# MDR32F8 register map
Vendor: Milandr; File version: 1.0
CPU: CM4 r1p1, little endian, no MPU, FPU, 3 interrupt priority bits
Registers are 32-bit, read-write, reset 0x0 unless marked. A register's access mark holds for its fields unless they carry their own. Offsets are from the block's base; [hi:lo] are bit positions; {n}, {i} and the like mark numbered series.

## MDR_EEPROM — Flash programm memory interfase controller registers
Base 0x40018000; register names take the prefix MDR_EEPROM_
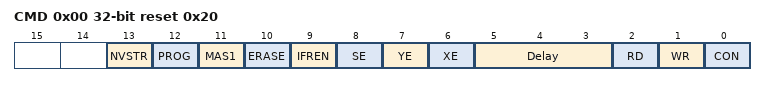
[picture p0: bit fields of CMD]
0x00 CMD reset 0x20 — EEPROM Command Register
  [13] NVSTR, [12] PROG, [11] MAS1, [10] ERASE, [9] IFREN, [8] SE, [7] YE, [6] XE, [5:3] Delay, [2] RD, [1] WR, [0] CON
0x04 ADR — EEPROM Address Register
0x08 DI — EEPROM Read Data Register
  [31:0] DATA
0x0C DO — EEPROM Write Data Register
  [31:0] DATA
0x10 KEY — EEPROM Key Register

## MDR_RST_CLK — RST_CLK
Base 0x40020000; register names take the prefix MDR_RST_CLK_
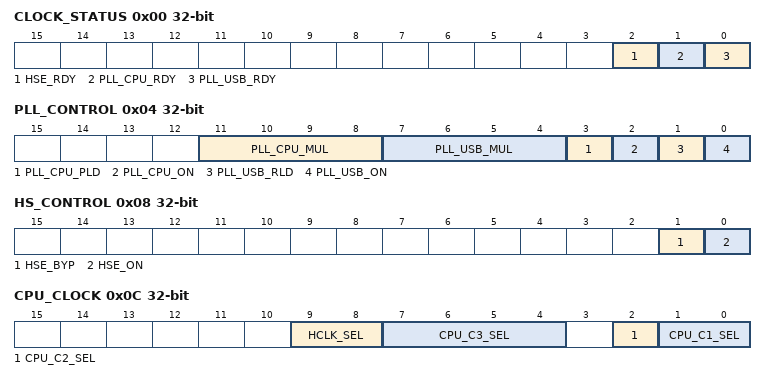
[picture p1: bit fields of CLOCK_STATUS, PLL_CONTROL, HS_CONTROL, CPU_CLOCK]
0x00 CLOCK_STATUS ro
  [2] HSE_RDY, [1] PLL_CPU_RDY, [0] PLL_USB_RDY
0x04 PLL_CONTROL
  [11:8] PLL_CPU_MUL, [7:4] PLL_USB_MUL, [3] PLL_CPU_PLD, [2] PLL_CPU_ON, [1] PLL_USB_RLD, [0] PLL_USB_ON
0x08 HS_CONTROL
  [1] HSE_BYP, [0] HSE_ON
0x0C CPU_CLOCK
  [9:8] HCLK_SEL, [7:4] CPU_C3_SEL, [2] CPU_C2_SEL, [1:0] CPU_C1_SEL
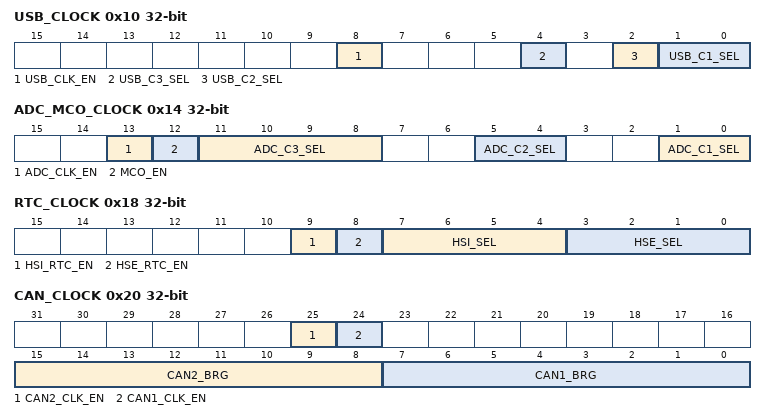
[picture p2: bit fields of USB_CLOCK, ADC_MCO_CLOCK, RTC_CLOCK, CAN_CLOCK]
0x10 USB_CLOCK
  [8] USB_CLK_EN, [4] USB_C3_SEL, [2] USB_C2_SEL, [1:0] USB_C1_SEL
0x14 ADC_MCO_CLOCK — ADC Clock Register
  [13] ADC_CLK_EN, [12] MCO_EN, [11:8] ADC_C3_SEL, [5:4] ADC_C2_SEL, [1:0] ADC_C1_SEL
0x18 RTC_CLOCK
  [9] HSI_RTC_EN, [8] HSE_RTC_EN, [7:4] HSI_SEL, [3:0] HSE_SEL
0x1C PER_CLOCK — Peripheral Clock Enable Register
  [31:0] PCLK_EN
0x20 CAN_CLOCK
  [25] CAN2_CLK_EN, [24] CAN1_CLK_EN, [15:8] CAN2_BRG, [7:0] CAN1_BRG
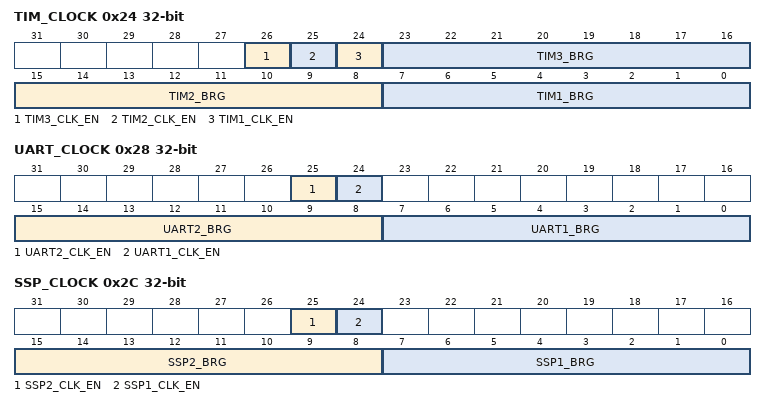
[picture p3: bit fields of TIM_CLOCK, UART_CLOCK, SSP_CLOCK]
0x24 TIM_CLOCK — Timer Clock Register
  [26] TIM3_CLK_EN, [25] TIM2_CLK_EN, [24] TIM1_CLK_EN, [23:16] TIM3_BRG, [15:8] TIM2_BRG, [7:0] TIM1_BRG
0x28 UART_CLOCK
  [25] UART2_CLK_EN, [24] UART1_CLK_EN, [15:8] UART2_BRG, [7:0] UART1_BRG
0x2C SSP_CLOCK
  [25] SSP2_CLK_EN, [24] SSP1_CLK_EN, [15:8] SSP2_BRG, [7:0] SSP1_BRG

## MDR_WDT — Watch Dog Timer
Base 0x40004000
0x00 KEY — Key lock Register
0x04 PRL
0x08 EN — EN Register: Counter run - 0x03333
0x0C CNT

## MDR_EBC — External Bus Control
Base 0x40005000
0x00 KEY — Key lock Register
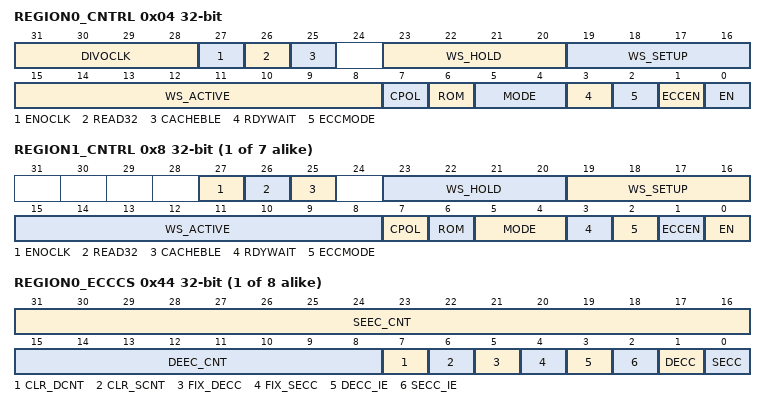
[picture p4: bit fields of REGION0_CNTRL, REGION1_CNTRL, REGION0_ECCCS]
0x04 REGION0_CNTRL
  [31:28] DIVOCLK
  [27] ENOCLK — 0 - OCL OFF, 1 - OCL ON
  [26] READ32
  [25] CACHEBLE — 0 - CACHEBLE OFF, 1 - CACHEBLE ON
  [23:20] WS_HOLD — T = HCLK*(WS_HOLD+1)
  [19:16] WS_SETUP — T = HCLK*(WS_SETUP+1)
  [15:8] WS_ACTIVE — T = HCLK*(WS_ACTIVE+1)
  [7] CPOL — Clock in Active: 0 - Rise, 1 - Fall
  [6] ROM — 0 - RAM, 1 - ROM
  [5:4] MODE — MODE[1:0]: 00 - 32, 01 - 16, 10 - 8, 11 - 64
  [3] RDYWAIT
  [2] ECCMODE — 0 - parallel ECC, 1 - serial ECC
  [1] ECCEN — 0 - ECC OFF, 1 - ECC ON
  [0] EN — 0 - Region OFF, 1 - Region ON
{0x4+4i} REGION{i}_CNTRL (i=1..7)
  [27] ENOCLK — 0 - OCL OFF, 1 - OCL ON
  [26] READ32
  [25] CACHEBLE — 0 - CACHEBLE OFF, 1 - CACHEBLE ON
  [23:20] WS_HOLD — T = HCLK*(WS_HOLD+1)
  [19:16] WS_SETUP — T = HCLK*(WS_SETUP+1)
  [15:8] WS_ACTIVE — T = HCLK*(WS_ACTIVE+1)
  [7] CPOL — Clock in Active: 0 - Rise, 1 - Fall
  [6] ROM — 0 - RAM, 1 - ROM
  [5:4] MODE — MODE[1:0]: 00 - 32, 01 - 16, 10 - 8, 11 - 64
  [3] RDYWAIT
  [2] ECCMODE — 0 - parallel ECC, 1 - serial ECC
  [1] ECCEN — 0 - ECC OFF, 1 - ECC ON
  [0] EN — 0 - Region OFF, 1 - Region ON
{0x24+4i} REGION{i}_ECCBASE (i=0..7)
{0x44+4i} REGION{i}_ECCCS (i=0..7)
  [31:16] SEEC_CNT, [15:8] DEEC_CNT, [7] CLR_DCNT, [6] CLR_SCNT, [5] FIX_DECC, [4] FIX_SECC, [3] DECC_IE, [2] SECC_IE, [1] DECC, [0] SECC
0x94 ECCADR
0x98 ECCDATA
0x9C ECCECC (reset mask 0xFF)

## MDR_OTP — OTP Memory Control
Base 0x40006000
0x00 KEY — Key lock Register
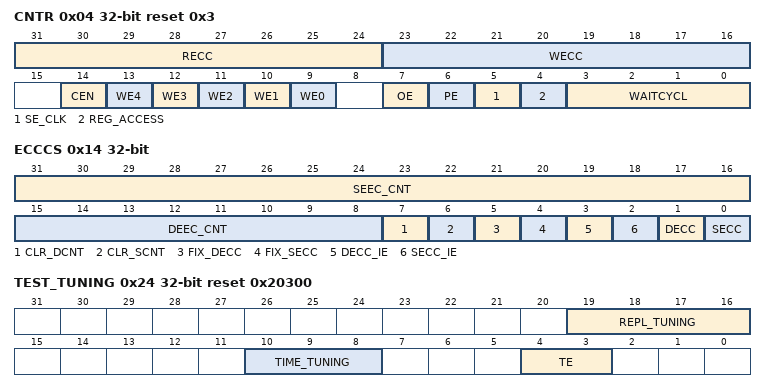
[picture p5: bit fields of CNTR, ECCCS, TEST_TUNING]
0x04 CNTR reset 0x3
  [31:24] RECC
  [23:16] WECC
  [14] CEN — CEN only for RAM (1986VE81T)
  [n+9] WE{n} (n=0..4) — WE only for RAM (1986VE81T)
  [7] OE — OE only for RAM (1986VE81T)
  [6] PE — PE only for OTP (1986VE8T)
  [5] SE_CLK — SE for OTP (1986VE8T), CLK for RAM (1986VE81T)
  [4] REG_ACCESS
  [3:0] WAITCYCL
0x08 ADR
0x0C WDATA
  [31:0] DATA
0x10 RDATA
  [31:0] DATA
0x14 ECCCS
  [31:16] SEEC_CNT, [15:8] DEEC_CNT, [7] CLR_DCNT, [6] CLR_SCNT, [5] FIX_DECC, [4] FIX_SECC, [3] DECC_IE, [2] SECC_IE, [1] DECC, [0] SECC
0x18 ECCADR
0x1C ECCDATA
0x20 ECCECC
  [7:0] ECC
0x24 TEST_TUNING reset 0x20300
  [19:16] REPL_TUNING, [10:8] TIME_TUNING, [4:3] TE

## MDR_RAMD — RAMD Control
Base 0x40008000
Same registers: MDR_ROM 0x40009000
0x00 KEY — Key lock Register
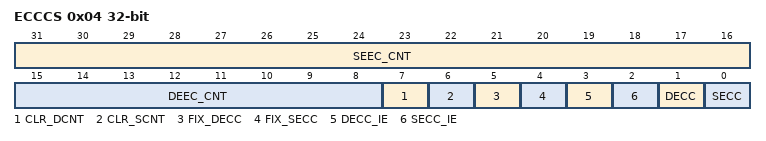
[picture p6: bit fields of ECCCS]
0x04 ECCCS
  [31:16] SEEC_CNT, [15:8] DEEC_CNT, [7] CLR_DCNT, [6] CLR_SCNT, [5] FIX_DECC, [4] FIX_SECC, [3] DECC_IE, [2] SECC_IE, [1] DECC, [0] SECC
0x08 ECCADR
0x0C ECCDATA
0x10 ECCECC
  [7:0] ECC
0x14 TEST_TUNING reset 0x2
  [2:0] TUNE

## MDR_ICACHE — I-BUS Cache Controller
Base 0xE0044000
Same registers: MDR_SCACHE 0x4000B000, MDR_DCACHE 0xE0045000
0x00 KEY — Key lock Register
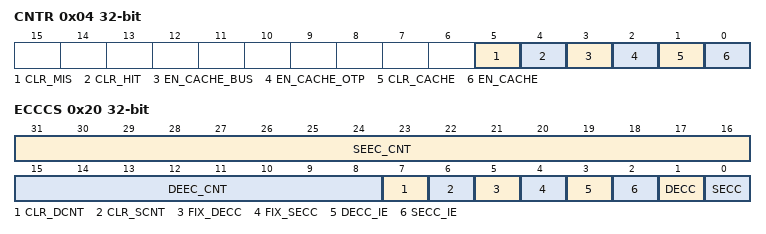
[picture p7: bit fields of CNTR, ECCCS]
0x04 CNTR
  [5] CLR_MIS, [4] CLR_HIT, [3] EN_CACHE_BUS, [2] EN_CACHE_OTP, [1] CLR_CACHE, [0] EN_CACHE
0x08 HIT_CNT
0x0C MISS_CNT
0x20 ECCCS
  [31:16] SEEC_CNT, [15:8] DEEC_CNT, [7] CLR_DCNT, [6] CLR_SCNT, [5] FIX_DECC, [4] FIX_SECC, [3] DECC_IE, [2] SECC_IE, [1] DECC, [0] SECC
0x24 ECCADR
0x28 ECCDATA
0x2C ECCECC
  [7:0] ECC
